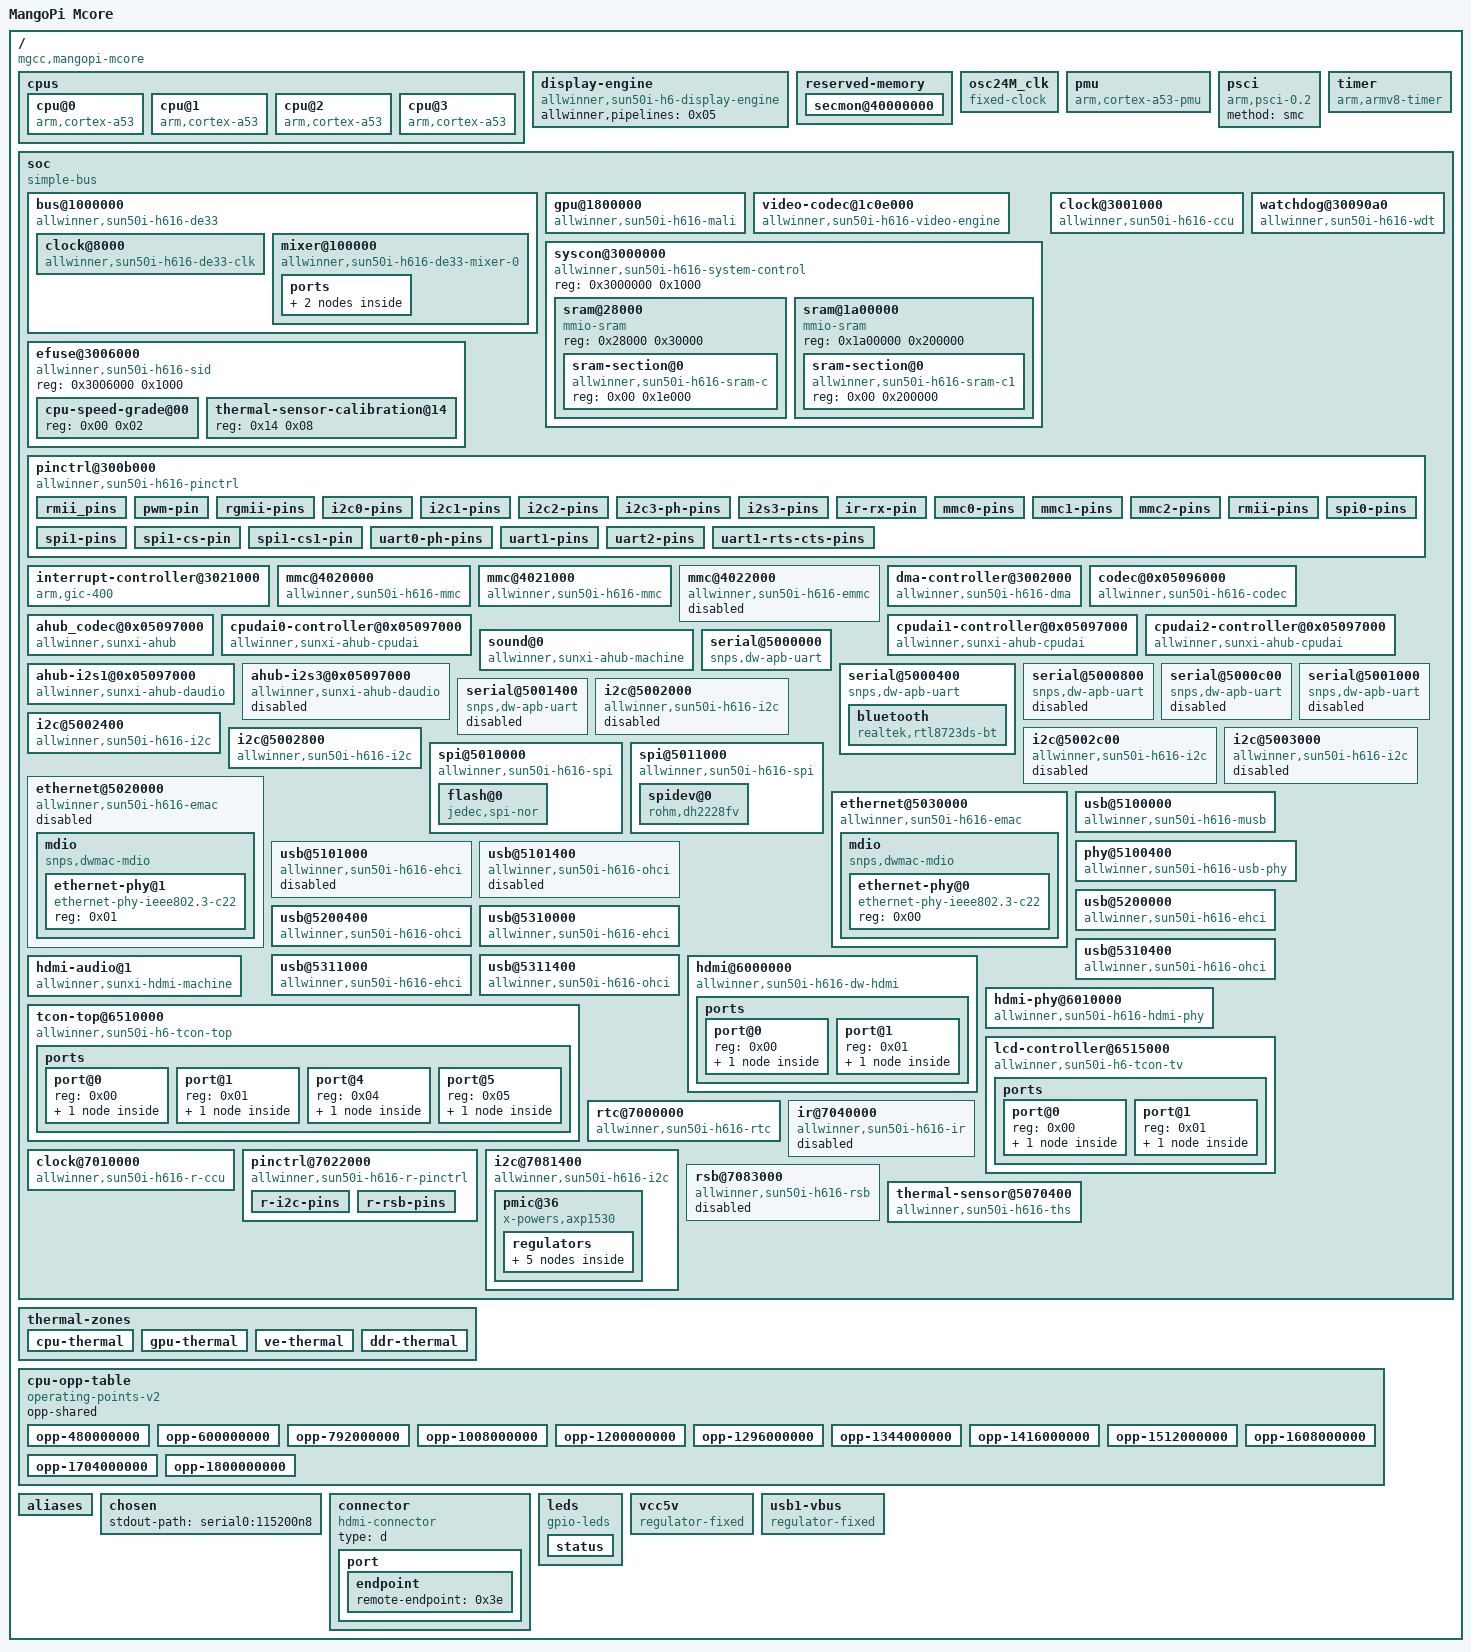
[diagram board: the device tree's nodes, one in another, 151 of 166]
/dts-v1/;

/ {
	interrupt-parent = <0x01>;
	#address-cells = <0x02>;
	#size-cells = <0x02>;
	model = "MangoPi Mcore";
	compatible = "mgcc,mangopi-mcore\0allwinner,sun50i-h616";

	cpus {
		#address-cells = <0x01>;
		#size-cells = <0x00>;

		cpu@0 {
			compatible = "arm,cortex-a53";
			device_type = "cpu";
			reg = <0x00>;
			enable-method = "psci";
			clocks = <0x02 0x15>;
			clock-latency-ns = <0x3b9b0>;
			operating-points-v2 = <0x03>;
			cpu-supply = <0x04>;
			status = "okay";
			phandle = <0x06>;
		};

		cpu@1 {
			compatible = "arm,cortex-a53";
			device_type = "cpu";
			reg = <0x01>;
			enable-method = "psci";
			clocks = <0x02 0x15>;
			clock-latency-ns = <0x3b9b0>;
			operating-points-v2 = <0x03>;
			phandle = <0x07>;
		};

		cpu@2 {
			compatible = "arm,cortex-a53";
			device_type = "cpu";
			reg = <0x02>;
			enable-method = "psci";
			clocks = <0x02 0x15>;
			clock-latency-ns = <0x3b9b0>;
			operating-points-v2 = <0x03>;
			phandle = <0x08>;
		};

		cpu@3 {
			compatible = "arm,cortex-a53";
			device_type = "cpu";
			reg = <0x03>;
			enable-method = "psci";
			clocks = <0x02 0x15>;
			clock-latency-ns = <0x3b9b0>;
			operating-points-v2 = <0x03>;
			phandle = <0x09>;
		};
	};

	display-engine {
		compatible = "allwinner,sun50i-h6-display-engine";
		allwinner,pipelines = <0x05>;
		status = "okay";
		phandle = <0x3f>;
	};

	reserved-memory {
		#address-cells = <0x02>;
		#size-cells = <0x02>;
		ranges;

		secmon@40000000 {
			reg = <0x00 0x40000000 0x00 0x80000>;
			no-map;
			phandle = <0x40>;
		};
	};

	osc24M_clk {
		#clock-cells = <0x00>;
		compatible = "fixed-clock";
		clock-frequency = <0x16e3600>;
		clock-output-names = "osc24M";
		phandle = <0x0f>;
	};

	pmu {
		compatible = "arm,cortex-a53-pmu";
		interrupts = <0x00 0x8c 0x04 0x00 0x8d 0x04 0x00 0x8e 0x04 0x00 0x8f 0x04>;
		interrupt-affinity = <0x06 0x07 0x08 0x09>;
	};

	psci {
		compatible = "arm,psci-0.2";
		method = "smc";
	};

	timer {
		compatible = "arm,armv8-timer";
		arm,no-tick-in-suspend;
		interrupts = <0x01 0x0d 0xf04 0x01 0x0e 0xf04 0x01 0x0b 0xf04 0x01 0x0a 0xf04>;
	};

	soc {
		compatible = "simple-bus";
		#address-cells = <0x01>;
		#size-cells = <0x01>;
		ranges = <0x00 0x00 0x00 0x40000000>;

		bus@1000000 {
			compatible = "allwinner,sun50i-h616-de33\0allwinner,sun50i-a64-de2";
			reg = <0x1000000 0x400000>;
			allwinner,sram = <0x0a 0x01>;
			#address-cells = <0x01>;
			#size-cells = <0x01>;
			ranges = <0x00 0x1000000 0x400000>;

			clock@8000 {
				compatible = "allwinner,sun50i-h616-de33-clk";
				reg = <0x8000 0x100>;
				clocks = <0x02 0x1d 0x02 0x1e>;
				clock-names = "mod\0bus";
				resets = <0x02 0x01>;
				#clock-cells = <0x01>;
				#reset-cells = <0x01>;
				phandle = <0x0b>;
			};

			mixer@100000 {
				compatible = "allwinner,sun50i-h616-de33-mixer-0";
				reg = <0x100000 0x100000 0x8100 0x40 0x280000 0x20000>;
				clocks = <0x0b 0x00 0x0b 0x06>;
				clock-names = "bus\0mod";
				resets = <0x0b 0x00>;
				phandle = <0x05>;

				ports {
					#address-cells = <0x01>;
					#size-cells = <0x00>;

					port@1 {
						reg = <0x01>;
						phandle = <0x41>;

						endpoint {
							remote-endpoint = <0x0c>;
							phandle = <0x31>;
						};
					};
				};
			};
		};

		gpu@1800000 {
			compatible = "allwinner,sun50i-h616-mali\0arm,mali-bifrost";
			reg = <0x1800000 0x40000>;
			interrupts = <0x00 0x5f 0x04 0x00 0x60 0x04 0x00 0x61 0x04>;
			interrupt-names = "job\0mmu\0gpu";
			clocks = <0x02 0x23 0x02 0x24>;
			clock-names = "core\0bus";
			resets = <0x02 0x03>;
			status = "okay";
			mali-supply = <0x0d>;
			phandle = <0x42>;
		};

		video-codec@1c0e000 {
			compatible = "allwinner,sun50i-h616-video-engine";
			reg = <0x1c0e000 0x2000>;
			clocks = <0x02 0x29 0x02 0x28 0x02 0x33>;
			clock-names = "ahb\0mod\0ram";
			resets = <0x02 0x05>;
			interrupts = <0x00 0x5d 0x04>;
			allwinner,sram = <0x0e 0x01>;
		};

		syscon@3000000 {
			compatible = "allwinner,sun50i-h616-system-control";
			reg = <0x3000000 0x1000>;
			#address-cells = <0x01>;
			#size-cells = <0x01>;
			ranges;
			phandle = <0x27>;

			sram@28000 {
				compatible = "mmio-sram";
				reg = <0x28000 0x30000>;
				#address-cells = <0x01>;
				#size-cells = <0x01>;
				ranges = <0x00 0x28000 0x30000>;
				phandle = <0x43>;

				sram-section@0 {
					compatible = "allwinner,sun50i-h616-sram-c\0allwinner,sun50i-a64-sram-c";
					reg = <0x00 0x1e000>;
					phandle = <0x0a>;
				};
			};

			sram@1a00000 {
				compatible = "mmio-sram";
				reg = <0x1a00000 0x200000>;
				#address-cells = <0x01>;
				#size-cells = <0x01>;
				ranges = <0x00 0x1a00000 0x200000>;
				phandle = <0x44>;

				sram-section@0 {
					compatible = "allwinner,sun50i-h616-sram-c1";
					reg = <0x00 0x200000>;
					phandle = <0x0e>;
				};
			};
		};

		clock@3001000 {
			compatible = "allwinner,sun50i-h616-ccu";
			reg = <0x3001000 0x1000>;
			clocks = <0x0f 0x10 0x00 0x10 0x02>;
			clock-names = "hosc\0losc\0iosc";
			#clock-cells = <0x01>;
			#reset-cells = <0x01>;
			phandle = <0x02>;
		};

		efuse@3006000 {
			compatible = "allwinner,sun50i-h616-sid";
			reg = <0x3006000 0x1000>;
			#address-cells = <0x01>;
			#size-cells = <0x01>;
			phandle = <0x45>;

			cpu-speed-grade@00 {
				reg = <0x00 0x02>;
				phandle = <0x46>;
			};

			thermal-sensor-calibration@14 {
				reg = <0x14 0x08>;
				phandle = <0x3c>;
			};
		};

		watchdog@30090a0 {
			compatible = "allwinner,sun50i-h616-wdt\0allwinner,sun6i-a31-wdt";
			reg = <0x30090a0 0x20>;
			interrupts = <0x00 0x32 0x04>;
			clocks = <0x0f>;
			status = "okay";
			phandle = <0x47>;
		};

		pinctrl@300b000 {
			compatible = "allwinner,sun50i-h616-pinctrl";
			reg = <0x300b000 0x400>;
			interrupts = <0x00 0x33 0x04 0x00 0x34 0x04 0x00 0x35 0x04 0x00 0x2b 0x04 0x00 0x36 0x04 0x00 0x37 0x04 0x00 0x38 0x04 0x00 0x39 0x04>;
			clocks = <0x02 0x1a 0x0f 0x10 0x00>;
			clock-names = "apb\0hosc\0losc";
			gpio-controller;
			#gpio-cells = <0x03>;
			interrupt-controller;
			#interrupt-cells = <0x03>;
			phandle = <0x13>;

			rmii_pins {
				pins = "PI2\0PI3\0PI5\0PI6\0PI9\0PI10\0PI11\0PI12\0PI14\0PI15";
				function = "emac0";
				drive-strength = <0x28>;
				phandle = <0x48>;
			};

			pwm-pin {
				pins = "PA12";
				function = "pwm5";
				phandle = <0x49>;
			};

			rgmii-pins {
				pins = "PI0\0PI1\0PI2\0PI3\0PI4\0PI5\0PI7\0PI8\0PI9\0PI10\0PI11\0PI12\0PI13\0PI14\0PI15\0PI16";
				function = "emac0";
				drive-strength = <0x28>;
				phandle = <0x28>;
			};

			i2c0-pins {
				pins = "PI6\0PI7";
				function = "i2c0";
				phandle = <0x21>;
			};

			i2c1-pins {
				pins = "PI7\0PI8";
				function = "i2c1";
				phandle = <0x22>;
			};

			i2c2-pins {
				pins = "PI9\0PI10";
				function = "i2c2";
				phandle = <0x23>;
			};

			i2c3-ph-pins {
				pins = "PH4\0PH5";
				function = "i2c3";
				phandle = <0x4a>;
			};

			i2s3-pins {
				pins = "PH5\0PH6\0PH7\0PH8\0PH9";
				function = "i2s3";
				phandle = <0x1c>;
			};

			ir-rx-pin {
				pins = "PH10";
				function = "ir_rx";
				phandle = <0x39>;
			};

			mmc0-pins {
				pins = "PF0\0PF1\0PF2\0PF3\0PF4\0PF5";
				function = "mmc0";
				drive-strength = <0x1e>;
				bias-pull-up;
				phandle = <0x11>;
			};

			mmc1-pins {
				pins = "PG0\0PG1\0PG2\0PG3\0PG4\0PG5";
				function = "mmc1";
				drive-strength = <0x1e>;
				bias-pull-up;
				phandle = <0x14>;
			};

			mmc2-pins {
				pins = "PC0\0PC1\0PC5\0PC6\0PC8\0PC9\0PC10\0PC11\0PC13\0PC14\0PC15\0PC16";
				function = "mmc2";
				drive-strength = <0x1e>;
				bias-pull-up;
				phandle = <0x15>;
			};

			rmii-pins {
				pins = "PA0\0PA1\0PA2\0PA3\0PA4\0PA5\0PA6\0PA7\0PA8\0PA9";
				function = "emac1";
				drive-strength = <0x28>;
				phandle = <0x2a>;
			};

			spi0-pins {
				pins = "PC0\0PC2\0PC3\0PC4";
				function = "spi0";
				phandle = <0x24>;
			};

			spi1-pins {
				pins = "PH6\0PH7\0PH8";
				function = "spi1";
				phandle = <0x25>;
			};

			spi1-cs-pin {
				pins = "PH5";
				function = "spi1";
				phandle = <0x26>;
			};

			spi1-cs1-pin {
				pins = "PH9";
				function = "spi1";
				phandle = <0x4b>;
			};

			uart0-ph-pins {
				pins = "PH0\0PH1";
				function = "uart0";
				phandle = <0x1d>;
			};

			uart1-pins {
				pins = "PG6\0PG7";
				function = "uart1";
				phandle = <0x1e>;
			};

			uart2-pins {
				pins = "PI5\0PI6";
				function = "uart2";
				phandle = <0x20>;
			};

			uart1-rts-cts-pins {
				pins = "PG8\0PG9";
				function = "uart1";
				phandle = <0x1f>;
			};
		};

		interrupt-controller@3021000 {
			compatible = "arm,gic-400";
			reg = <0x3021000 0x1000 0x3022000 0x2000 0x3024000 0x2000 0x3026000 0x2000>;
			interrupts = <0x01 0x09 0xf04>;
			interrupt-controller;
			#interrupt-cells = <0x03>;
			phandle = <0x01>;
		};

		mmc@4020000 {
			compatible = "allwinner,sun50i-h616-mmc\0allwinner,sun50i-a100-mmc";
			reg = <0x4020000 0x1000>;
			clocks = <0x02 0x3f 0x02 0x3c>;
			clock-names = "ahb\0mmc";
			resets = <0x02 0x0e>;
			reset-names = "ahb";
			interrupts = <0x00 0x23 0x04>;
			pinctrl-names = "default";
			pinctrl-0 = <0x11>;
			status = "okay";
			max-frequency = <0x8f0d180>;
			cap-sd-highspeed;
			cap-mmc-highspeed;
			mmc-ddr-3_3v;
			mmc-ddr-1_8v;
			cap-sdio-irq;
			#address-cells = <0x01>;
			#size-cells = <0x00>;
			vmmc-supply = <0x12>;
			cd-gpios = <0x13 0x05 0x06 0x01>;
			bus-width = <0x04>;
			phandle = <0x4c>;
		};

		mmc@4021000 {
			compatible = "allwinner,sun50i-h616-mmc\0allwinner,sun50i-a100-mmc";
			reg = <0x4021000 0x1000>;
			clocks = <0x02 0x40 0x02 0x3d>;
			clock-names = "ahb\0mmc";
			resets = <0x02 0x0f>;
			reset-names = "ahb";
			interrupts = <0x00 0x24 0x04>;
			pinctrl-names = "default";
			pinctrl-0 = <0x14>;
			status = "okay";
			max-frequency = <0x8f0d180>;
			cap-sd-highspeed;
			cap-mmc-highspeed;
			mmc-ddr-3_3v;
			mmc-ddr-1_8v;
			cap-sdio-irq;
			#address-cells = <0x01>;
			#size-cells = <0x00>;
			vmmc-supply = <0x12>;
			vqmmc-supply = <0x12>;
			bus-width = <0x04>;
			non-removable;
			phandle = <0x4d>;
		};

		mmc@4022000 {
			compatible = "allwinner,sun50i-h616-emmc\0allwinner,sun50i-a100-emmc";
			reg = <0x4022000 0x1000>;
			clocks = <0x02 0x41 0x02 0x3e>;
			clock-names = "ahb\0mmc";
			resets = <0x02 0x10>;
			reset-names = "ahb";
			interrupts = <0x00 0x25 0x04>;
			pinctrl-names = "default";
			pinctrl-0 = <0x15>;
			status = "disabled";
			max-frequency = <0x8f0d180>;
			cap-sd-highspeed;
			cap-mmc-highspeed;
			mmc-ddr-3_3v;
			mmc-ddr-1_8v;
			cap-sdio-irq;
			#address-cells = <0x01>;
			#size-cells = <0x00>;
			vmmc-supply = <0x12>;
			vqmmc-supply = <0x16>;
			bus-width = <0x08>;
			non-removable;
			cap-mmc-hw-reset;
			mmc-hs200-1_8v;
			phandle = <0x4e>;
		};

		dma-controller@3002000 {
			compatible = "allwinner,sun50i-h616-dma";
			reg = <0x3002000 0x1000>;
			interrupts = <0x00 0x2a 0x04>;
			clocks = <0x02 0x2a 0x02 0x32>;
			clock-names = "bus\0mbus";
			dma-channels = <0x10>;
			dma-requests = <0x31>;
			resets = <0x02 0x06>;
			#dma-cells = <0x01>;
			phandle = <0x17>;
		};

		codec@0x05096000 {
			#sound-dai-cells = <0x00>;
			compatible = "allwinner,sun50i-h616-codec";
			reg = <0x5096000 0x31c>;
			interrupts = <0x00 0x3a 0x04>;
			clocks = <0x02 0x5d 0x02 0x5b 0x02 0x5c>;
			clock-names = "apb\0audio-codec-1x\0audio-codec-4x";
			resets = <0x02 0x24>;
			dmas = <0x17 0x06>;
			dma-names = "tx";
			status = "okay";
			allwinner,audio-routing = "Line Out\0LINEOUT";
			phandle = <0x4f>;
		};

		ahub_codec@0x05097000 {
			compatible = "allwinner,sunxi-ahub";
			reg = <0x5097000 0xadf>;
			clocks = <0x02 0x5f 0x02 0x5b 0x02 0x5c 0x02 0x5e>;
			clock-names = "apb\0audio-codec-1x\0audio-codec-4x\0audio-hub";
			resets = <0x02 0x25>;
			status = "okay";
			phandle = <0x1b>;
		};

		cpudai0-controller@0x05097000 {
			compatible = "allwinner,sunxi-ahub-cpudai";
			reg = <0x5097000 0xadf>;
			id = <0x00>;
			dmas = <0x17 0x03 0x17 0x03>;
			dma-names = "rx\0tx";
			status = "okay";
			phandle = <0x18>;
		};

		cpudai1-controller@0x05097000 {
			compatible = "allwinner,sunxi-ahub-cpudai";
			reg = <0x5097000 0xadf>;
			id = <0x01>;
			dmas = <0x17 0x04 0x17 0x04>;
			dma-names = "rx\0tx";
			status = "okay";
			phandle = <0x19>;
		};

		cpudai2-controller@0x05097000 {
			compatible = "allwinner,sunxi-ahub-cpudai";
			reg = <0x5097000 0xadf>;
			id = <0x02>;
			dmas = <0x17 0x05 0x17 0x05>;
			dma-names = "rx\0tx";
			status = "okay";
			phandle = <0x1a>;
		};

		sound@0 {
			compatible = "allwinner,sunxi-ahub-machine";
			sunxi,cpudai-controller0 = <0x18>;
			sunxi,cpudai-controller1 = <0x19>;
			sunxi,cpudai-controller2 = <0x1a>;
			sunxi,audio-codec = <0x1b>;
			status = "okay";
			phandle = <0x50>;
		};

		ahub-i2s1@0x05097000 {
			#sound-dai-cells = <0x00>;
			compatible = "allwinner,sunxi-ahub-daudio";
			reg = <0x5097000 0xadf>;
			clocks = <0x02 0x5f 0x02 0x5b 0x02 0x5c 0x02 0x5e>;
			clock-names = "apb\0audio-codec-1x\0audio-codec-4x\0audio-hub";
			tdm_num = <0x01>;
			pinconfig = <0x00>;
			frametype = <0x00>;
			pcm_lrck_period = <0x20>;
			slot_width_select = <0x20>;
			daudio_master = <0x04>;
			audio_format = <0x01>;
			signal_inversion = <0x01>;
			tdm_config = <0x01>;
			mclk_div = <0x01>;
			status = "okay";
			phandle = <0x2d>;
		};

		ahub-i2s3@0x05097000 {
			compatible = "allwinner,sunxi-ahub-daudio";
			reg = <0x5097000 0xadf>;
			clocks = <0x02 0x5f 0x02 0x5b 0x02 0x5c 0x02 0x5e>;
			clock-names = "apb\0audio-codec-1x\0audio-codec-4x\0audio-hub";
			pinctrl-names = "default";
			pinctrl-0 = <0x1c>;
			tdm_num = <0x03>;
			pinconfig = <0x01>;
			frametype = <0x00>;
			pcm_lrck_period = <0x20>;
			slot_width_select = <0x20>;
			daudio_master = <0x04>;
			audio_format = <0x01>;
			signal_inversion = <0x01>;
			tdm_config = <0x01>;
			mclk_div = <0x04>;
			status = "disabled";
			phandle = <0x51>;
		};

		serial@5000000 {
			compatible = "snps,dw-apb-uart";
			reg = <0x5000000 0x400>;
			interrupts = <0x00 0x00 0x04>;
			reg-shift = <0x02>;
			reg-io-width = <0x04>;
			clocks = <0x02 0x42>;
			resets = <0x02 0x11>;
			status = "okay";
			pinctrl-names = "default";
			pinctrl-0 = <0x1d>;
			phandle = <0x52>;
		};

		serial@5000400 {
			compatible = "snps,dw-apb-uart";
			reg = <0x5000400 0x400>;
			interrupts = <0x00 0x01 0x04>;
			reg-shift = <0x02>;
			reg-io-width = <0x04>;
			clocks = <0x02 0x43>;
			resets = <0x02 0x12>;
			status = "okay";
			uart-has-rtscts;
			pinctrl-0 = <0x1e 0x1f>;
			pinctrl-names = "default";
			phandle = <0x53>;

			bluetooth {
				compatible = "realtek,rtl8723ds-bt";
				device-wake-gpios = <0x13 0x06 0x11 0x00>;
				enable-gpios = <0x13 0x06 0x13 0x00>;
				host-wake-gpios = <0x13 0x06 0x10 0x00>;
			};
		};

		serial@5000800 {
			compatible = "snps,dw-apb-uart";
			reg = <0x5000800 0x400>;
			interrupts = <0x00 0x02 0x04>;
			reg-shift = <0x02>;
			reg-io-width = <0x04>;
			clocks = <0x02 0x44>;
			resets = <0x02 0x13>;
			status = "disabled";
			pinctrl-names = "default";
			pinctrl-0 = <0x20>;
			phandle = <0x54>;
		};

		serial@5000c00 {
			compatible = "snps,dw-apb-uart";
			reg = <0x5000c00 0x400>;
			interrupts = <0x00 0x03 0x04>;
			reg-shift = <0x02>;
			reg-io-width = <0x04>;
			clocks = <0x02 0x45>;
			resets = <0x02 0x14>;
			status = "disabled";
			phandle = <0x55>;
		};

		serial@5001000 {
			compatible = "snps,dw-apb-uart";
			reg = <0x5001000 0x400>;
			interrupts = <0x00 0x04 0x04>;
			reg-shift = <0x02>;
			reg-io-width = <0x04>;
			clocks = <0x02 0x46>;
			resets = <0x02 0x15>;
			status = "disabled";
			phandle = <0x56>;
		};

		serial@5001400 {
			compatible = "snps,dw-apb-uart";
			reg = <0x5001400 0x400>;
			interrupts = <0x00 0x05 0x04>;
			reg-shift = <0x02>;
			reg-io-width = <0x04>;
			clocks = <0x02 0x47>;
			resets = <0x02 0x16>;
			status = "disabled";
			phandle = <0x57>;
		};

		i2c@5002000 {
			compatible = "allwinner,sun50i-h616-i2c\0allwinner,sun6i-a31-i2c";
			reg = <0x5002000 0x400>;
			interrupts = <0x00 0x06 0x04>;
			clocks = <0x02 0x48>;
			resets = <0x02 0x17>;
			pinctrl-names = "default";
			pinctrl-0 = <0x21>;
			status = "disabled";
			#address-cells = <0x01>;
			#size-cells = <0x00>;
			phandle = <0x58>;
		};

		i2c@5002400 {
			compatible = "allwinner,sun50i-h616-i2c\0allwinner,sun6i-a31-i2c";
			reg = <0x5002400 0x400>;
			interrupts = <0x00 0x07 0x04>;
			clocks = <0x02 0x49>;
			resets = <0x02 0x18>;
			status = "okay";
			#address-cells = <0x01>;
			#size-cells = <0x00>;
			pinctrl-names = "default";
			pinctrl-0 = <0x22>;
			phandle = <0x59>;
		};

		i2c@5002800 {
			compatible = "allwinner,sun50i-h616-i2c\0allwinner,sun6i-a31-i2c";
			reg = <0x5002800 0x400>;
			interrupts = <0x00 0x08 0x04>;
			clocks = <0x02 0x4a>;
			resets = <0x02 0x19>;
			status = "okay";
			#address-cells = <0x01>;
			#size-cells = <0x00>;
			pinctrl-names = "default";
			pinctrl-0 = <0x23>;
			phandle = <0x5a>;
		};

		i2c@5002c00 {
			compatible = "allwinner,sun50i-h616-i2c\0allwinner,sun6i-a31-i2c";
			reg = <0x5002c00 0x400>;
			interrupts = <0x00 0x09 0x04>;
			clocks = <0x02 0x4b>;
			resets = <0x02 0x1a>;
			status = "disabled";
			#address-cells = <0x01>;
			#size-cells = <0x00>;
			phandle = <0x5b>;
		};

		i2c@5003000 {
			compatible = "allwinner,sun50i-h616-i2c\0allwinner,sun6i-a31-i2c";
			reg = <0x5003000 0x400>;
			interrupts = <0x00 0x0a 0x04>;
			clocks = <0x02 0x4c>;
			resets = <0x02 0x1b>;
			status = "disabled";
			#address-cells = <0x01>;
			#size-cells = <0x00>;
			phandle = <0x5c>;
		};

		spi@5010000 {
			compatible = "allwinner,sun50i-h616-spi\0allwinner,sun8i-h3-spi";
			reg = <0x5010000 0x1000>;
			interrupts = <0x00 0x0c 0x04>;
			clocks = <0x02 0x4f 0x02 0x4d>;
			clock-names = "ahb\0mod";
			resets = <0x02 0x1c>;
			pinctrl-names = "default";
			pinctrl-0 = <0x24>;
			status = "okay";
			#address-cells = <0x01>;
			#size-cells = <0x00>;
			phandle = <0x5d>;

			flash@0 {
				#address-cells = <0x01>;
				#size-cells = <0x01>;
				compatible = "jedec,spi-nor";
				reg = <0x00>;
				spi-max-frequency = <0x2625a00>;
			};
		};

		spi@5011000 {
			compatible = "allwinner,sun50i-h616-spi\0allwinner,sun8i-h3-spi";
			reg = <0x5011000 0x1000>;
			interrupts = <0x00 0x0d 0x04>;
			clocks = <0x02 0x50 0x02 0x4e>;
			clock-names = "ahb\0mod";
			resets = <0x02 0x1d>;
			pinctrl-names = "default";
			pinctrl-0 = <0x25 0x26>;
			status = "okay";
			#address-cells = <0x01>;
			#size-cells = <0x00>;
			phandle = <0x5e>;

			spidev@0 {
				compatible = "rohm,dh2228fv";
				status = "okay";
				reg = <0x00>;
				spi-max-frequency = <0x1e8480>;
			};
		};

		ethernet@5020000 {
			compatible = "allwinner,sun50i-h616-emac\0allwinner,sun50i-a64-emac";
			syscon = <0x27>;
			reg = <0x5020000 0x10000>;
			interrupts = <0x00 0x0e 0x04>;
			interrupt-names = "macirq";
			resets = <0x02 0x1e>;
			reset-names = "stmmaceth";
			clocks = <0x02 0x52>;
			clock-names = "stmmaceth";
			status = "disabled";
			pinctrl-names = "default";
			pinctrl-0 = <0x28>;
			phy-mode = "rgmii";
			phy-handle = <0x29>;
			phy-supply = <0x12>;
			allwinner,rx-delay-ps = <0xc1c>;
			allwinner,tx-delay-ps = <0x2bc>;
			phandle = <0x5f>;

			mdio {
				compatible = "snps,dwmac-mdio";
				#address-cells = <0x01>;
				#size-cells = <0x00>;
				phandle = <0x60>;

				ethernet-phy@1 {
					compatible = "ethernet-phy-ieee802.3-c22";
					reg = <0x01>;
					phandle = <0x29>;
				};
			};
		};

		ethernet@5030000 {
			compatible = "allwinner,sun50i-h616-emac";
			syscon = <0x27 0x01>;
			reg = <0x5030000 0x10000>;
			interrupts = <0x00 0x0f 0x04>;
			interrupt-names = "macirq";
			resets = <0x02 0x1f>;
			reset-names = "stmmaceth";
			clocks = <0x02 0x53>;
			clock-names = "stmmaceth";
			status = "okay";
			pinctrl-names = "default";
			pinctrl-0 = <0x2a>;
			phy-mode = "rmii";
			phy-handle = <0x2b>;
			phy-supply = <0x12>;
			allwinner,rx-delay-ps = <0xc1c>;
			allwinner,tx-delay-ps = <0x2bc>;
			phandle = <0x61>;

			mdio {
				compatible = "snps,dwmac-mdio";
				#address-cells = <0x01>;
				#size-cells = <0x00>;
				phandle = <0x62>;

				ethernet-phy@0 {
					compatible = "ethernet-phy-ieee802.3-c22";
					reg = <0x00>;
					phandle = <0x2b>;
				};
			};
		};

		usb@5100000 {
			compatible = "allwinner,sun50i-h616-musb\0allwinner,sun8i-h3-musb";
			reg = <0x5100000 0x400>;
			clocks = <0x02 0x70>;
			resets = <0x02 0x32>;
			interrupts = <0x00 0x19 0x04>;
			interrupt-names = "mc";
			phys = <0x2c 0x00>;
			phy-names = "usb";
			extcon = <0x2c 0x00>;
			status = "okay";
			dr_mode = "peripheral";
			phandle = <0x63>;
		};

		phy@5100400 {
			compatible = "allwinner,sun50i-h616-usb-phy";
			reg = <0x5100400 0x24 0x5101800 0x14 0x5200800 0x14 0x5310800 0x14 0x5311800 0x14>;
			reg-names = "phy_ctrl\0pmu0\0pmu1\0pmu2\0pmu3";
			clocks = <0x02 0x61 0x02 0x63 0x02 0x65 0x02 0x67 0x02 0x6e>;
			clock-names = "usb0_phy\0usb1_phy\0usb2_phy\0usb3_phy\0pmu2_clk";
			resets = <0x02 0x26 0x02 0x27 0x02 0x28 0x02 0x29>;
			reset-names = "usb0_reset\0usb1_reset\0usb2_reset\0usb3_reset";
			status = "okay";
			#phy-cells = <0x01>;
			phandle = <0x2c>;
		};

		usb@5101000 {
			compatible = "allwinner,sun50i-h616-ehci\0generic-ehci";
			reg = <0x5101000 0x100>;
			interrupts = <0x00 0x1a 0x04>;
			clocks = <0x02 0x68 0x02 0x6c 0x02 0x60 0x02 0x65>;
			resets = <0x02 0x2a 0x02 0x2e 0x02 0x28>;
			phys = <0x2c 0x00>;
			phy-names = "usb";
			status = "disabled";
			phandle = <0x64>;
		};

		usb@5101400 {
			compatible = "allwinner,sun50i-h616-ohci\0generic-ohci";
			reg = <0x5101400 0x100>;
			interrupts = <0x00 0x1b 0x04>;
			clocks = <0x02 0x68 0x02 0x60 0x02 0x65>;
			resets = <0x02 0x2a 0x02 0x28>;
			phys = <0x2c 0x00>;
			phy-names = "usb";
			status = "disabled";
			phandle = <0x65>;
		};

		usb@5200000 {
			compatible = "allwinner,sun50i-h616-ehci\0generic-ehci";
			reg = <0x5200000 0x100>;
			interrupts = <0x00 0x1c 0x04>;
			clocks = <0x02 0x69 0x02 0x6d 0x02 0x62 0x02 0x65>;
			resets = <0x02 0x2b 0x02 0x2f 0x02 0x28>;
			phys = <0x2c 0x01>;
			phy-names = "usb";
			status = "okay";
			phandle = <0x66>;
		};

		usb@5200400 {
			compatible = "allwinner,sun50i-h616-ohci\0generic-ohci";
			reg = <0x5200400 0x100>;
			interrupts = <0x00 0x1d 0x04>;
			clocks = <0x02 0x69 0x02 0x62 0x02 0x65>;
			resets = <0x02 0x2b 0x02 0x28>;
			phys = <0x2c 0x01>;
			phy-names = "usb";
			status = "okay";
			phandle = <0x67>;
		};

		usb@5310000 {
			compatible = "allwinner,sun50i-h616-ehci\0generic-ehci";
			reg = <0x5310000 0x100>;
			interrupts = <0x00 0x1e 0x04>;
			clocks = <0x02 0x6a 0x02 0x6e 0x02 0x64>;
			resets = <0x02 0x2c 0x02 0x30>;
			phys = <0x2c 0x02>;
			phy-names = "usb";
			status = "okay";
			phandle = <0x68>;
		};

		usb@5310400 {
			compatible = "allwinner,sun50i-h616-ohci\0generic-ohci";
			reg = <0x5310400 0x100>;
			interrupts = <0x00 0x1f 0x04>;
			clocks = <0x02 0x6a 0x02 0x64>;
			resets = <0x02 0x2c>;
			phys = <0x2c 0x02>;
			phy-names = "usb";
			status = "okay";
			phandle = <0x69>;
		};

		usb@5311000 {
			compatible = "allwinner,sun50i-h616-ehci\0generic-ehci";
			reg = <0x5311000 0x100>;
			interrupts = <0x00 0x20 0x04>;
			clocks = <0x02 0x6b 0x02 0x6f 0x02 0x66 0x02 0x65>;
			resets = <0x02 0x2d 0x02 0x31 0x02 0x28>;
			phys = <0x2c 0x03>;
			phy-names = "usb";
			status = "okay";
			phandle = <0x6a>;
		};

		usb@5311400 {
			compatible = "allwinner,sun50i-h616-ohci\0generic-ohci";
			reg = <0x5311400 0x100>;
			interrupts = <0x00 0x21 0x04>;
			clocks = <0x02 0x6b 0x02 0x66 0x02 0x65>;
			resets = <0x02 0x2d 0x02 0x28>;
			phys = <0x2c 0x03>;
			phy-names = "usb";
			status = "okay";
			phandle = <0x6b>;
		};

		hdmi-audio@1 {
			compatible = "allwinner,sunxi-hdmi-machine";
			sunxi,cpudai-controller = <0x2d>;
			sunxi,snddaudio-codec = "hdmi-audio-codec.4.auto";
			status = "okay";
			phandle = <0x6c>;
		};

		hdmi@6000000 {
			compatible = "allwinner,sun50i-h616-dw-hdmi\0allwinner,sun50i-h6-dw-hdmi";
			reg = <0x6000000 0x10000>;
			reg-io-width = <0x01>;
			interrupts = <0x00 0x3f 0x04>;
			clocks = <0x02 0x75 0x02 0x73 0x02 0x72 0x02 0x74 0x02 0x7e 0x02 0x7f>;
			clock-names = "iahb\0isfr\0tmds\0cec\0hdcp\0hdcp-bus";
			resets = <0x02 0x33 0x02 0x3a>;
			reset-names = "ctrl\0hdcp";
			phys = <0x2e>;
			phy-names = "phy";
			status = "okay";
			aw-hdmi-codec-quirk;
			hvcc-supply = <0x16>;
			phandle = <0x6d>;

			ports {
				#address-cells = <0x01>;
				#size-cells = <0x00>;

				port@0 {
					reg = <0x00>;
					phandle = <0x6e>;

					endpoint {
						remote-endpoint = <0x2f>;
						phandle = <0x34>;
					};
				};

				port@1 {
					reg = <0x01>;
					phandle = <0x6f>;

					endpoint {
						remote-endpoint = <0x30>;
						phandle = <0x3e>;
					};
				};
			};
		};

		hdmi-phy@6010000 {
			compatible = "allwinner,sun50i-h616-hdmi-phy";
			reg = <0x6010000 0x10000>;
			clocks = <0x02 0x75 0x02 0x73>;
			clock-names = "bus\0mod";
			resets = <0x02 0x34>;
			reset-names = "phy";
			#phy-cells = <0x00>;
			phandle = <0x2e>;
		};

		tcon-top@6510000 {
			compatible = "allwinner,sun50i-h6-tcon-top";
			reg = <0x6510000 0x1000>;
			clocks = <0x02 0x76 0x02 0x77>;
			clock-names = "bus\0tcon-tv0";
			clock-output-names = "tcon-top-tv0";
			resets = <0x02 0x35>;
			#clock-cells = <0x01>;
			phandle = <0x35>;

			ports {
				#address-cells = <0x01>;
				#size-cells = <0x00>;

				port@0 {
					#address-cells = <0x01>;
					#size-cells = <0x00>;
					reg = <0x00>;
					phandle = <0x70>;

					endpoint@0 {
						reg = <0x00>;
						remote-endpoint = <0x31>;
						phandle = <0x0c>;
					};
				};

				port@1 {
					#address-cells = <0x01>;
					#size-cells = <0x00>;
					reg = <0x01>;
					phandle = <0x71>;

					endpoint@2 {
						reg = <0x02>;
						remote-endpoint = <0x32>;
						phandle = <0x36>;
					};
				};

				port@4 {
					#address-cells = <0x01>;
					#size-cells = <0x00>;
					reg = <0x04>;
					phandle = <0x72>;

					endpoint@0 {
						reg = <0x00>;
						remote-endpoint = <0x33>;
						phandle = <0x37>;
					};
				};

				port@5 {
					reg = <0x05>;
					phandle = <0x73>;

					endpoint {
						remote-endpoint = <0x34>;
						phandle = <0x2f>;
					};
				};
			};
		};

		lcd-controller@6515000 {
			compatible = "allwinner,sun50i-h6-tcon-tv\0allwinner,sun8i-r40-tcon-tv";
			reg = <0x6515000 0x1000>;
			interrupts = <0x00 0x42 0x04>;
			clocks = <0x02 0x79 0x35 0x00>;
			clock-names = "ahb\0tcon-ch1";
			resets = <0x02 0x36>;
			reset-names = "lcd";
			phandle = <0x74>;

			ports {
				#address-cells = <0x01>;
				#size-cells = <0x00>;

				port@0 {
					reg = <0x00>;
					phandle = <0x75>;

					endpoint {
						remote-endpoint = <0x36>;
						phandle = <0x32>;
					};
				};

				port@1 {
					#address-cells = <0x01>;
					#size-cells = <0x00>;
					reg = <0x01>;
					phandle = <0x76>;

					endpoint@1 {
						reg = <0x01>;
						remote-endpoint = <0x37>;
						phandle = <0x33>;
					};
				};
			};
		};

		rtc@7000000 {
			compatible = "allwinner,sun50i-h616-rtc";
			reg = <0x7000000 0x400>;
			interrupts = <0x00 0x65 0x04 0x00 0x66 0x04>;
			clock-output-names = "osc32k\0osc32k-out\0iosc";
			#clock-cells = <0x01>;
			phandle = <0x10>;
		};

		clock@7010000 {
			compatible = "allwinner,sun50i-h616-r-ccu";
			reg = <0x7010000 0x210>;
			clocks = <0x0f 0x10 0x00 0x10 0x02 0x02 0x04>;
			clock-names = "hosc\0losc\0iosc\0pll-periph";
			#clock-cells = <0x01>;
			#reset-cells = <0x01>;
			phandle = <0x38>;
		};

		pinctrl@7022000 {
			compatible = "allwinner,sun50i-h616-r-pinctrl";
			reg = <0x7022000 0x400>;
			interrupts = <0x00 0x2b 0x04>;
			clocks = <0x38 0x02 0x0f 0x10 0x00>;
			clock-names = "apb\0hosc\0losc";
			gpio-controller;
			#gpio-cells = <0x03>;
			interrupt-controller;
			#interrupt-cells = <0x03>;
			phandle = <0x77>;

			r-i2c-pins {
				pins = "PL0\0PL1";
				function = "s_i2c";
				phandle = <0x78>;
			};

			r-rsb-pins {
				pins = "PL0\0PL1";
				function = "s_rsb";
				phandle = <0x3b>;
			};
		};

		ir@7040000 {
			compatible = "allwinner,sun50i-h616-ir\0allwinner,sun6i-a31-ir";
			reg = <0x7040000 0x400>;
			interrupts = <0x00 0x6a 0x04>;
			clocks = <0x38 0x09 0x38 0x0b>;
			clock-names = "apb\0ir";
			resets = <0x38 0x05>;
			pinctrl-names = "default";
			pinctrl-0 = <0x39>;
			status = "disabled";
			phandle = <0x79>;
		};

		i2c@7081400 {
			compatible = "allwinner,sun50i-h616-i2c\0allwinner,sun6i-a31-i2c";
			reg = <0x7081400 0x400>;
			interrupts = <0x00 0x69 0x04>;
			clocks = <0x38 0x08>;
			resets = <0x38 0x04>;
			status = "okay";
			#address-cells = <0x01>;
			#size-cells = <0x00>;
			phandle = <0x7a>;

			pmic@36 {
				compatible = "x-powers,axp1530";
				reg = <0x36>;
				interrupt-controller;
				#interrupt-cells = <0x01>;
				vin1-supply = <0x3a>;
				vin2-supply = <0x3a>;
				vin3-supply = <0x3a>;
				ldo1in-supply = <0x3a>;
				ldo2in-supply = <0x3a>;
				phandle = <0x7b>;

				regulators {

					ldo2 {
						regulator-always-on;
						regulator-min-microvolt = <0x325aa0>;
						regulator-max-microvolt = <0x325aa0>;
						regulator-name = "vcc-sys";
						phandle = <0x12>;
					};

					ldo1 {
						regulator-always-on;
						regulator-min-microvolt = <0x1b7740>;
						regulator-max-microvolt = <0x1b7740>;
						regulator-name = "vcc1v8";
						phandle = <0x16>;
					};

					dcdc2 {
						regulator-always-on;
						regulator-min-microvolt = <0xc5c10>;
						regulator-max-microvolt = <0x124f80>;
						regulator-name = "vdd-cpu";
						phandle = <0x04>;
					};

					dcdc1 {
						regulator-always-on;
						regulator-min-microvolt = <0xc5c10>;
						regulator-max-microvolt = <0x11b340>;
						regulator-name = "vdd-gpu-sys";
						phandle = <0x0d>;
					};

					dcdc3 {
						regulator-always-on;
						regulator-min-microvolt = <0x16e360>;
						regulator-max-microvolt = <0x16e360>;
						regulator-name = "vdd-dram";
						phandle = <0x7c>;
					};
				};
			};
		};

		rsb@7083000 {
			compatible = "allwinner,sun50i-h616-rsb\0allwinner,sun8i-a23-rsb";
			reg = <0x7083000 0x400>;
			interrupts = <0x00 0x6d 0x04>;
			clocks = <0x38 0x0d>;
			clock-frequency = <0x2dc6c0>;
			resets = <0x38 0x07>;
			pinctrl-names = "default";
			pinctrl-0 = <0x3b>;
			status = "disabled";
			#address-cells = <0x01>;
			#size-cells = <0x00>;
			phandle = <0x7d>;
		};

		thermal-sensor@5070400 {
			compatible = "allwinner,sun50i-h616-ths";
			reg = <0x5070400 0x400>;
			interrupts = <0x00 0x13 0x04>;
			clocks = <0x02 0x56>;
			clock-names = "bus";
			resets = <0x02 0x21>;
			nvmem-cells = <0x3c>;
			nvmem-cell-names = "calibration";
			#thermal-sensor-cells = <0x01>;
			phandle = <0x3d>;
		};
	};

	thermal-zones {

		cpu-thermal {
			polling-delay-passive = <0x1f4>;
			polling-delay = <0x3e8>;
			thermal-sensors = <0x3d 0x02>;
			sustainable-power = <0x3e8>;
			k_po = <0x14>;
			k_pu = <0x28>;
			k_i = <0x00>;
		};

		gpu-thermal {
			polling-delay-passive = <0x00>;
			polling-delay = <0x00>;
			thermal-sensors = <0x3d 0x00>;
		};

		ve-thermal {
			polling-delay-passive = <0x00>;
			polling-delay = <0x00>;
			thermal-sensors = <0x3d 0x01>;
		};

		ddr-thermal {
			polling-delay-passive = <0x00>;
			polling-delay = <0x00>;
			thermal-sensors = <0x3d 0x03>;
		};
	};

	cpu-opp-table {
		compatible = "operating-points-v2";
		opp-shared;
		phandle = <0x03>;

		opp-480000000 {
			clock-latency-ns = <0x3b9b0>;
			opp-hz = <0x00 0x1c9c3800>;
			opp-microvolt = <0xc8320 0xc8320 0x124f80>;
		};

		opp-600000000 {
			clock-latency-ns = <0x3b9b0>;
			opp-hz = <0x00 0x23c34600>;
			opp-microvolt = <0xc8320 0xc8320 0x124f80>;
		};

		opp-792000000 {
			clock-latency-ns = <0x3b9b0>;
			opp-hz = <0x00 0x2f34f600>;
			opp-microvolt = <0xd1f60 0xd1f60 0x124f80>;
		};

		opp-1008000000 {
			clock-latency-ns = <0x3b9b0>;
			opp-hz = <0x00 0x3c14dc00>;
			opp-microvolt = <0xdbba0 0xdbba0 0x124f80>;
		};

		opp-1200000000 {
			clock-latency-ns = <0x3b9b0>;
			opp-hz = <0x00 0x47868c00>;
			opp-microvolt = <0xea600 0xea600 0x124f80>;
		};

		opp-1296000000 {
			clock-latency-ns = <0x3b9b0>;
			opp-hz = <0x00 0x4d3f6400>;
			opp-microvolt = <0x111700 0x111700 0x124f80>;
		};

		opp-1344000000 {
			clock-latency-ns = <0x3b9b0>;
			opp-hz = <0x00 0x501bd000>;
			opp-microvolt = <0x111700 0x111700 0x124f80>;
		};

		opp-1416000000 {
			clock-latency-ns = <0x3b9b0>;
			opp-hz = <0x00 0x54667200>;
			opp-microvolt = <0x111700 0x111700 0x124f80>;
		};

		opp-1512000000 {
			clock-latency-ns = <0x3b9b0>;
			opp-hz = <0x00 0x5a1f4a00>;
			opp-microvolt = <0x111700 0x111700 0x124f80>;
		};

		opp-1608000000 {
			clock-latency-ns = <0x3b9b0>;
			opp-hz = <0x00 0x5fd82200>;
			opp-microvolt = <0x11b340 0x11b340 0x124f80>;
		};

		opp-1704000000 {
			clock-latency-ns = <0x3b9b0>;
			opp-hz = <0x00 0x6590fa00>;
			opp-microvolt = <0x120160 0x120160 0x124f80>;
		};

		opp-1800000000 {
			clock-latency-ns = <0x3b9b0>;
			opp-hz = <0x00 0x6b49d200>;
			opp-microvolt = <0x124f80 0x124f80 0x124f80>;
		};
	};

	aliases {
		ethernet0 = "/soc/ethernet@5020000";
		ethernet1 = "/soc/ethernet@5030000";
		serial0 = "/soc/serial@5000000";
		serial1 = "/soc/serial@5000800";
		mmc0 = "/soc/mmc@4020000";
		mmc1 = "/soc/mmc@4021000";
	};

	chosen {
		stdout-path = "serial0:115200n8";
	};

	connector {
		compatible = "hdmi-connector";
		type = "d";

		port {

			endpoint {
				remote-endpoint = <0x3e>;
				phandle = <0x30>;
			};
		};
	};

	leds {
		compatible = "gpio-leds";

		status {
			label = "led_red";
			linux,default-trigger = "heartbeat";
			gpios = <0x13 0x02 0x0d 0x00>;
			default-state = "on";
		};
	};

	vcc5v {
		compatible = "regulator-fixed";
		regulator-name = "vcc-5v";
		regulator-min-microvolt = <0x4c4b40>;
		regulator-max-microvolt = <0x4c4b40>;
		regulator-always-on;
		phandle = <0x3a>;
	};

	usb1-vbus {
		compatible = "regulator-fixed";
		regulator-name = "usb1-vbus";
		regulator-min-microvolt = <0x4c4b40>;
		regulator-max-microvolt = <0x4c4b40>;
		enable-active-high;
		gpio = <0x13 0x02 0x08 0x00>;
		status = "okay";
		phandle = <0x7e>;
	};

	__symbols__ {
		cpu0 = "/cpus/cpu@0";
		cpu1 = "/cpus/cpu@1";
		cpu2 = "/cpus/cpu@2";
		cpu3 = "/cpus/cpu@3";
		de = "/display-engine";
		secmon_reserved = "/reserved-memory/secmon@40000000";
		osc24M = "/osc24M_clk";
		display_clocks = "/soc/bus@1000000/clock@8000";
		mixer0 = "/soc/bus@1000000/mixer@100000";
		mixer0_out = "/soc/bus@1000000/mixer@100000/ports/port@1";
		mixer0_out_tcon_top_mixer0 = "/soc/bus@1000000/mixer@100000/ports/port@1/endpoint";
		gpu = "/soc/gpu@1800000";
		syscon = "/soc/syscon@3000000";
		sram_c = "/soc/syscon@3000000/sram@28000";
		de3_sram = "/soc/syscon@3000000/sram@28000/sram-section@0";
		sram_c1 = "/soc/syscon@3000000/sram@1a00000";
		ve_sram = "/soc/syscon@3000000/sram@1a00000/sram-section@0";
		ccu = "/soc/clock@3001000";
		sid = "/soc/efuse@3006000";
		cpu_speed_grade = "/soc/efuse@3006000/cpu-speed-grade@00";
		ths_calibration = "/soc/efuse@3006000/thermal-sensor-calibration@14";
		watchdog = "/soc/watchdog@30090a0";
		pio = "/soc/pinctrl@300b000";
		ext_rmii_pins = "/soc/pinctrl@300b000/rmii_pins";
		pwm1_pin = "/soc/pinctrl@300b000/pwm-pin";
		ext_rgmii_pins = "/soc/pinctrl@300b000/rgmii-pins";
		i2c0_pins = "/soc/pinctrl@300b000/i2c0-pins";
		i2c1_pins = "/soc/pinctrl@300b000/i2c1-pins";
		i2c2_pins = "/soc/pinctrl@300b000/i2c2-pins";
		i2c3_ph_pins = "/soc/pinctrl@300b000/i2c3-ph-pins";
		i2s3_pins = "/soc/pinctrl@300b000/i2s3-pins";
		ir_rx_pin = "/soc/pinctrl@300b000/ir-rx-pin";
		mmc0_pins = "/soc/pinctrl@300b000/mmc0-pins";
		mmc1_pins = "/soc/pinctrl@300b000/mmc1-pins";
		mmc2_pins = "/soc/pinctrl@300b000/mmc2-pins";
		rmii_pins = "/soc/pinctrl@300b000/rmii-pins";
		spi0_pins = "/soc/pinctrl@300b000/spi0-pins";
		spi1_pins = "/soc/pinctrl@300b000/spi1-pins";
		spi1_cs_pin = "/soc/pinctrl@300b000/spi1-cs-pin";
		spi1_cs1_pin = "/soc/pinctrl@300b000/spi1-cs1-pin";
		uart0_ph_pins = "/soc/pinctrl@300b000/uart0-ph-pins";
		uart1_pins = "/soc/pinctrl@300b000/uart1-pins";
		uart2_pins = "/soc/pinctrl@300b000/uart2-pins";
		uart1_rts_cts_pins = "/soc/pinctrl@300b000/uart1-rts-cts-pins";
		gic = "/soc/interrupt-controller@3021000";
		mmc0 = "/soc/mmc@4020000";
		mmc1 = "/soc/mmc@4021000";
		mmc2 = "/soc/mmc@4022000";
		dma = "/soc/dma-controller@3002000";
		codec = "/soc/codec@0x05096000";
		ahub_codec = "/soc/ahub_codec@0x05097000";
		ahub_cpudai0 = "/soc/cpudai0-controller@0x05097000";
		ahub_cpudai1 = "/soc/cpudai1-controller@0x05097000";
		ahub_cpudai2 = "/soc/cpudai2-controller@0x05097000";
		sndahub = "/soc/sound@0";
		ahub_i2s1 = "/soc/ahub-i2s1@0x05097000";
		ahub_i2s3 = "/soc/ahub-i2s3@0x05097000";
		uart0 = "/soc/serial@5000000";
		uart1 = "/soc/serial@5000400";
		uart2 = "/soc/serial@5000800";
		uart3 = "/soc/serial@5000c00";
		uart4 = "/soc/serial@5001000";
		uart5 = "/soc/serial@5001400";
		i2c0 = "/soc/i2c@5002000";
		i2c1 = "/soc/i2c@5002400";
		i2c2 = "/soc/i2c@5002800";
		i2c3 = "/soc/i2c@5002c00";
		i2c4 = "/soc/i2c@5003000";
		spi0 = "/soc/spi@5010000";
		spi1 = "/soc/spi@5011000";
		emac0 = "/soc/ethernet@5020000";
		mdio0 = "/soc/ethernet@5020000/mdio";
		ext_rgmii_phy = "/soc/ethernet@5020000/mdio/ethernet-phy@1";
		emac1 = "/soc/ethernet@5030000";
		mdio1 = "/soc/ethernet@5030000/mdio";
		emd_rgmii_phy = "/soc/ethernet@5030000/mdio/ethernet-phy@0";
		usbotg = "/soc/usb@5100000";
		usbphy = "/soc/phy@5100400";
		ehci0 = "/soc/usb@5101000";
		ohci0 = "/soc/usb@5101400";
		ehci1 = "/soc/usb@5200000";
		ohci1 = "/soc/usb@5200400";
		ehci2 = "/soc/usb@5310000";
		ohci2 = "/soc/usb@5310400";
		ehci3 = "/soc/usb@5311000";
		ohci3 = "/soc/usb@5311400";
		hdmi_audio = "/soc/hdmi-audio@1";
		hdmi = "/soc/hdmi@6000000";
		hdmi_in = "/soc/hdmi@6000000/ports/port@0";
		hdmi_in_tcon_top = "/soc/hdmi@6000000/ports/port@0/endpoint";
		hdmi_out = "/soc/hdmi@6000000/ports/port@1";
		hdmi_out_con = "/soc/hdmi@6000000/ports/port@1/endpoint";
		hdmi_phy = "/soc/hdmi-phy@6010000";
		tcon_top = "/soc/tcon-top@6510000";
		tcon_top_mixer0_in = "/soc/tcon-top@6510000/ports/port@0";
		tcon_top_mixer0_in_mixer0 = "/soc/tcon-top@6510000/ports/port@0/endpoint@0";
		tcon_top_mixer0_out = "/soc/tcon-top@6510000/ports/port@1";
		tcon_top_mixer0_out_tcon_tv = "/soc/tcon-top@6510000/ports/port@1/endpoint@2";
		tcon_top_hdmi_in = "/soc/tcon-top@6510000/ports/port@4";
		tcon_top_hdmi_in_tcon_tv = "/soc/tcon-top@6510000/ports/port@4/endpoint@0";
		tcon_top_hdmi_out = "/soc/tcon-top@6510000/ports/port@5";
		tcon_top_hdmi_out_hdmi = "/soc/tcon-top@6510000/ports/port@5/endpoint";
		tcon_tv = "/soc/lcd-controller@6515000";
		tcon_tv_in = "/soc/lcd-controller@6515000/ports/port@0";
		tcon_tv_in_tcon_top_mixer0 = "/soc/lcd-controller@6515000/ports/port@0/endpoint";
		tcon_tv_out = "/soc/lcd-controller@6515000/ports/port@1";
		tcon_tv_out_tcon_top = "/soc/lcd-controller@6515000/ports/port@1/endpoint@1";
		rtc = "/soc/rtc@7000000";
		r_ccu = "/soc/clock@7010000";
		r_pio = "/soc/pinctrl@7022000";
		r_i2c_pins = "/soc/pinctrl@7022000/r-i2c-pins";
		r_rsb_pins = "/soc/pinctrl@7022000/r-rsb-pins";
		ir = "/soc/ir@7040000";
		r_i2c = "/soc/i2c@7081400";
		axp305 = "/soc/i2c@7081400/pmic@36";
		reg_aldo1 = "/soc/i2c@7081400/pmic@36/regulators/ldo2";
		reg_bldo1 = "/soc/i2c@7081400/pmic@36/regulators/ldo1";
		reg_dcdca = "/soc/i2c@7081400/pmic@36/regulators/dcdc2";
		reg_dcdcc = "/soc/i2c@7081400/pmic@36/regulators/dcdc1";
		reg_dcdcd = "/soc/i2c@7081400/pmic@36/regulators/dcdc3";
		r_rsb = "/soc/rsb@7083000";
		ths = "/soc/thermal-sensor@5070400";
		cpu_opp_table = "/cpu-opp-table";
		hdmi_con_in = "/connector/port/endpoint";
		reg_vcc5v = "/vcc5v";
		reg_usb1_vbus = "/usb1-vbus";
	};
};
